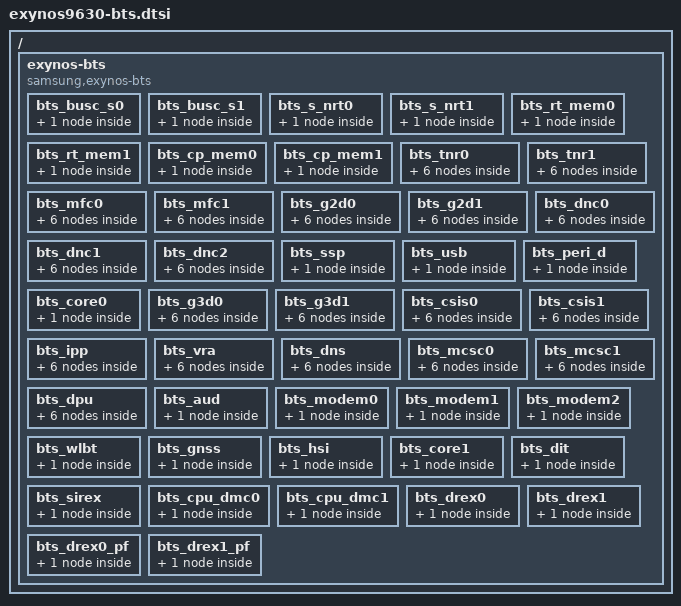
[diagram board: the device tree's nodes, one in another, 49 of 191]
/*
 * SAMSUNG EXYNOS SoC BTS device tree source
 *
 * Copyright (c) 2018 Samsung Electronics Co., Ltd.
 *		http://www.samsung.com
 *
 * SAMSUNG EXYNOS SoC BTS device nodes are listed in this file.
 * EXYNOS based board files should include this file.
 *
 * This program is free software; you can redistribute it and/or modify
 * it under the terms of the GNU General Public License version 2 as
 * published by the Free Software Foundation.
 *
 */

#include <dt-bindings/soc/samsung/exynos-bts.h>
/ {
	exynos-bts {
		compatible = "samsung,exynos-bts";
		#address-cells = <2>;
		#size-cells = <1>;
		ranges;

		list-scen = "default",
			    "mfc_uhd",
			    "g3d_performance",
			    "camera_default",
			    "camera_performance",
			    "camera_thermal";

		bts_busc_s0 {
			reg = <0x0 0x146D2000 0x100>;
			status = "okay";
			bts-type = <BUSC_BTS>;
			default {
				stat_on = <0>;
			};
		};
		bts_busc_s1 {
			reg = <0x0 0x146E2000 0x100>;
			status = "okay";
			bts-type = <BUSC_BTS>;
			default {
				stat_on = <0>;
			};
		};
		bts_s_nrt0 {
			reg = <0x0 0x12172000 0x100>;
			status = "okay";
			bts-type = <BUSC_BTS>;
			default {
				stat_on = <0>;
			};
		};
		bts_s_nrt1 {
			reg = <0x0 0x12182000 0x100>;
			status = "okay";
			bts-type = <BUSC_BTS>;
			default {
				stat_on = <0>;
			};
		};
		bts_rt_mem0 {
			reg = <0x0 0x12192000 0x100>;
			status = "okay";
			bts-type = <BUSC_BTS>;
			default {
				stat_on = <0>;
			};
		};
		bts_rt_mem1 {
			reg = <0x0 0x121A2000 0x100>;
			status = "okay";
			bts-type = <BUSC_BTS>;
			default {
				stat_on = <0>;
			};
		};
		bts_cp_mem0 {
			reg = <0x0 0x121B2000 0x100>;
			status = "okay";
			bts-type = <BUSC_BTS>;
			default {
				stat_on = <0>;
			};
		};
		bts_cp_mem1 {
			reg = <0x0 0x121C2000 0x100>;
			status = "okay";
			bts-type = <BUSC_BTS>;
			default {
				stat_on = <0>;
			};
		};

		bts_tnr0 {
			reg = <0x0 0x14600000 0x100>;
			status = "okay";
			bts-type = <IP_BTS>;
			default {
				stat_on = <1>;
				bypass = <0>;
				arqos = <0x4>;
				awqos = <0x4>;
				rmo = <0x8>;
				wmo = <0x8>;
				qurgent_on = <0>;
				blocking_on = <1>;
				qmax0_limit_r = <0x4>;
				qmax0_limit_w = <0x4>;
			};
			mfc_uhd {
				stat_on = <1>;
				bypass = <0>;
				arqos = <0x4>;
				awqos = <0x4>;
				rmo = <0x8>;
				wmo = <0x8>;
				qurgent_on = <0>;
				blocking_on = <1>;
				qmax0_limit_r = <0x4>;
				qmax0_limit_w = <0x4>;
			};
			g3d_performance {
				stat_on = <1>;
				bypass = <0>;
				arqos = <0x4>;
				awqos = <0x4>;
				rmo = <0x8>;
				wmo = <0x8>;
				qurgent_on = <0>;
				blocking_on = <1>;
				qmax0_limit_r = <0x4>;
				qmax0_limit_w = <0x4>;
			};
			camera_default {
				stat_on = <1>;
				bypass = <0>;
				arqos = <0x4>;
				awqos = <0x4>;
				rmo = <0x8>;
				wmo = <0x8>;
				qurgent_on = <0>;
				blocking_on = <1>;
				qmax0_limit_r = <0x4>;
				qmax0_limit_w = <0x4>;
			};
			camera_performance {
				stat_on = <1>;
				bypass = <0>;
				arqos = <0x4>;
				awqos = <0x4>;
				rmo = <0x8>;
				wmo = <0x8>;
				qurgent_on = <0>;
				blocking_on = <1>;
				qmax0_limit_r = <0x4>;
				qmax0_limit_w = <0x4>;
			};
			camera_thermal {
				stat_on = <1>;
				bypass = <0>;
				arqos = <0x4>;
				awqos = <0x4>;
				rmo = <0x8>;
				wmo = <0x8>;
				qurgent_on = <0>;
				blocking_on = <1>;
				qmax0_limit_r = <0x4>;
				qmax0_limit_w = <0x4>;
			};
		};
		bts_tnr1 {
			reg = <0x0 0x14610000 0x100>;
			status = "okay";
			bts-type = <IP_BTS>;
			default {
				stat_on = <1>;
				bypass = <0>;
				arqos = <0x4>;
				awqos = <0x4>;
				rmo = <0x8>;
				wmo = <0x8>;
				qurgent_on = <0>;
				blocking_on = <1>;
				qmax0_limit_r = <0x4>;
				qmax0_limit_w = <0x4>;
			};
			mfc_uhd {
				stat_on = <1>;
				bypass = <0>;
				arqos = <0x4>;
				awqos = <0x4>;
				rmo = <0x8>;
				wmo = <0x8>;
				qurgent_on = <0>;
				blocking_on = <1>;
				qmax0_limit_r = <0x4>;
				qmax0_limit_w = <0x4>;
			};
			g3d_performance {
				stat_on = <1>;
				bypass = <0>;
				arqos = <0x4>;
				awqos = <0x4>;
				rmo = <0x8>;
				wmo = <0x8>;
				qurgent_on = <0>;
				blocking_on = <1>;
				qmax0_limit_r = <0x4>;
				qmax0_limit_w = <0x4>;
			};
			camera_default {
				stat_on = <1>;
				bypass = <0>;
				arqos = <0x4>;
				awqos = <0x4>;
				rmo = <0x8>;
				wmo = <0x8>;
				qurgent_on = <0>;
				blocking_on = <1>;
				qmax0_limit_r = <0x4>;
				qmax0_limit_w = <0x4>;
			};
			camera_performance {
				stat_on = <1>;
				bypass = <0>;
				arqos = <0x4>;
				awqos = <0x4>;
				rmo = <0x8>;
				wmo = <0x8>;
				qurgent_on = <0>;
				blocking_on = <1>;
				qmax0_limit_r = <0x4>;
				qmax0_limit_w = <0x4>;
			};
			camera_thermal {
				stat_on = <1>;
				bypass = <0>;
				arqos = <0x4>;
				awqos = <0x4>;
				rmo = <0x8>;
				wmo = <0x8>;
				qurgent_on = <0>;
				blocking_on = <1>;
				qmax0_limit_r = <0x4>;
				qmax0_limit_w = <0x4>;
			};
		};
		bts_mfc0 {
			reg = <0x0 0x14620000 0x100>;
			status = "okay";
			bts-type = <IP_BTS>;
			default {
				stat_on = <1>;
				bypass = <0>;
				arqos = <0x4>;
				awqos = <0x4>;
				rmo = <0x8>;
				wmo = <0x8>;
				qurgent_on = <0>;
				blocking_on = <1>;
				qmax0_limit_r = <0x3>;
				qmax0_limit_w = <0x3>;
			};
			mfc_uhd {
				stat_on = <1>;
				bypass = <0>;
				arqos = <0x4>;
				awqos = <0x4>;
				rmo = <0x10>;
				wmo = <0x10>;
				qurgent_on = <0>;
				blocking_on = <1>;
				qmax0_limit_r = <0x3>;
				qmax0_limit_w = <0x3>;
			};
			g3d_performance {
				stat_on = <1>;
				bypass = <0>;
				arqos = <0x4>;
				awqos = <0x4>;
				rmo = <0x8>;
				wmo = <0x8>;
				qurgent_on = <0>;
				blocking_on = <1>;
				qmax0_limit_r = <0x3>;
				qmax0_limit_w = <0x3>;
			};
			camera_default {
				stat_on = <1>;
				bypass = <0>;
				arqos = <0x4>;
				awqos = <0x4>;
				rmo = <0x8>;
				wmo = <0x8>;
				qurgent_on = <0>;
				blocking_on = <1>;
				qmax0_limit_r = <0x3>;
				qmax0_limit_w = <0x3>;
			};
			camera_performance {
				stat_on = <1>;
				bypass = <0>;
				arqos = <0x4>;
				awqos = <0x4>;
				rmo = <0x8>;
				wmo = <0x8>;
				qurgent_on = <0>;
				blocking_on = <1>;
				qmax0_limit_r = <0x3>;
				qmax0_limit_w = <0x3>;
			};
			camera_thermal {
				stat_on = <1>;
				bypass = <0>;
				arqos = <0x4>;
				awqos = <0x4>;
				rmo = <0x8>;
				wmo = <0x8>;
				qurgent_on = <0>;
				blocking_on = <1>;
				qmax0_limit_r = <0x3>;
				qmax0_limit_w = <0x3>;
			};
		};
		bts_mfc1 {
			reg = <0x0 0x14630000 0x100>;
			status = "okay";
			bts-type = <IP_BTS>;
			default {
				stat_on = <1>;
				bypass = <0>;
				arqos = <0x4>;
				awqos = <0x4>;
				rmo = <0x8>;
				wmo = <0x8>;
				qurgent_on = <0>;
				blocking_on = <1>;
				qmax0_limit_r = <0x3>;
				qmax0_limit_w = <0x3>;
			};
			mfc_uhd {
				stat_on = <1>;
				bypass = <0>;
				arqos = <0x4>;
				awqos = <0x4>;
				rmo = <0x10>;
				wmo = <0x10>;
				qurgent_on = <0>;
				blocking_on = <1>;
				qmax0_limit_r = <0x3>;
				qmax0_limit_w = <0x3>;
			};
			g3d_performance {
				stat_on = <1>;
				bypass = <0>;
				arqos = <0x4>;
				awqos = <0x4>;
				rmo = <0x8>;
				wmo = <0x8>;
				qurgent_on = <0>;
				blocking_on = <1>;
				qmax0_limit_r = <0x3>;
				qmax0_limit_w = <0x3>;
			};
			camera_default {
				stat_on = <1>;
				bypass = <0>;
				arqos = <0x4>;
				awqos = <0x4>;
				rmo = <0x8>;
				wmo = <0x8>;
				qurgent_on = <0>;
				blocking_on = <1>;
				qmax0_limit_r = <0x3>;
				qmax0_limit_w = <0x3>;
			};
			camera_performance {
				stat_on = <1>;
				bypass = <0>;
				arqos = <0x4>;
				awqos = <0x4>;
				rmo = <0x8>;
				wmo = <0x8>;
				qurgent_on = <0>;
				blocking_on = <1>;
				qmax0_limit_r = <0x3>;
				qmax0_limit_w = <0x3>;
			};
			camera_thermal {
				stat_on = <1>;
				bypass = <0>;
				arqos = <0x4>;
				awqos = <0x4>;
				rmo = <0x8>;
				wmo = <0x8>;
				qurgent_on = <0>;
				blocking_on = <1>;
				qmax0_limit_r = <0x3>;
				qmax0_limit_w = <0x3>;
			};
		};
		bts_g2d0 {
			reg = <0x0 0x14640000 0x100>;
			status = "okay";
			bts-type = <IP_BTS>;
			default {
				stat_on = <1>;
				bypass = <0>;
				arqos = <0x4>;
				awqos = <0x4>;
				rmo = <0x10>;
				wmo = <0x10>;
				qurgent_on = <0>;
				blocking_on = <1>;
				qmax0_limit_r = <0x1>;
				qmax0_limit_w = <0x1>;
			};
			mfc_uhd {
				stat_on = <1>;
				bypass = <0>;
				arqos = <0x4>;
				awqos = <0x4>;
				rmo = <0x10>;
				wmo = <0x10>;
				qurgent_on = <0>;
				blocking_on = <1>;
				qmax0_limit_r = <0x1>;
				qmax0_limit_w = <0x1>;
			};
			g3d_performance {
				stat_on = <1>;
				bypass = <0>;
				arqos = <0x4>;
				awqos = <0x4>;
				rmo = <0x10>;
				wmo = <0x10>;
				qurgent_on = <0>;
				blocking_on = <1>;
				qmax0_limit_r = <0x1>;
				qmax0_limit_w = <0x1>;
			};
			camera_default {
				stat_on = <1>;
				bypass = <0>;
				arqos = <0x4>;
				awqos = <0x4>;
				rmo = <0x8>;
				wmo = <0x8>;
				qurgent_on = <0>;
				blocking_on = <1>;
				qmax0_limit_r = <0x1>;
				qmax0_limit_w = <0x1>;
			};
			camera_performance {
				stat_on = <1>;
				bypass = <0>;
				arqos = <0x4>;
				awqos = <0x4>;
				rmo = <0x8>;
				wmo = <0x8>;
				qurgent_on = <0>;
				blocking_on = <1>;
				qmax0_limit_r = <0x1>;
				qmax0_limit_w = <0x1>;
			};
			camera_thermal {
				stat_on = <1>;
				bypass = <0>;
				arqos = <0x4>;
				awqos = <0x4>;
				rmo = <0x8>;
				wmo = <0x8>;
				qurgent_on = <0>;
				blocking_on = <1>;
				qmax0_limit_r = <0x1>;
				qmax0_limit_w = <0x1>;
			};
		};
		bts_g2d1 {
			reg = <0x0 0x14650000 0x100>;
			status = "okay";
			bts-type = <IP_BTS>;
			default {
				stat_on = <1>;
				bypass = <0>;
				arqos = <0x4>;
				awqos = <0x4>;
				rmo = <0x8>;
				wmo = <0x8>;
				qurgent_on = <0>;
				blocking_on = <1>;
				qmax0_limit_r = <0x1>;
				qmax0_limit_w = <0x1>;
			};
			mfc_uhd {
				stat_on = <1>;
				bypass = <0>;
				arqos = <0x4>;
				awqos = <0x4>;
				rmo = <0x8>;
				wmo = <0x8>;
				qurgent_on = <0>;
				blocking_on = <1>;
				qmax0_limit_r = <0x1>;
				qmax0_limit_w = <0x1>;
			};
			g3d_performance {
				stat_on = <1>;
				bypass = <0>;
				arqos = <0x4>;
				awqos = <0x4>;
				rmo = <0x8>;
				wmo = <0x8>;
				qurgent_on = <0>;
				blocking_on = <1>;
				qmax0_limit_r = <0x1>;
				qmax0_limit_w = <0x1>;
			};
			camera_default {
				stat_on = <1>;
				bypass = <0>;
				arqos = <0x4>;
				awqos = <0x4>;
				rmo = <0x6>;
				wmo = <0x6>;
				qurgent_on = <0>;
				blocking_on = <1>;
				qmax0_limit_r = <0x1>;
				qmax0_limit_w = <0x1>;
			};
			camera_performance {
				stat_on = <1>;
				bypass = <0>;
				arqos = <0x4>;
				awqos = <0x4>;
				rmo = <0x6>;
				wmo = <0x6>;
				qurgent_on = <0>;
				blocking_on = <1>;
				qmax0_limit_r = <0x1>;
				qmax0_limit_w = <0x1>;
			};
			camera_thermal {
				stat_on = <1>;
				bypass = <0>;
				arqos = <0x4>;
				awqos = <0x4>;
				rmo = <0x6>;
				wmo = <0x6>;
				qurgent_on = <0>;
				blocking_on = <1>;
				qmax0_limit_r = <0x1>;
				qmax0_limit_w = <0x1>;
			};
		};
		bts_dnc0 {
			reg = <0x0 0x14660000 0x100>;
			status = "okay";
			bts-type = <IP_BTS>;
			default {
				stat_on = <1>;
				bypass = <0>;
				arqos = <0x4>;
				awqos = <0x4>;
				rmo = <0x8>;
				wmo = <0x8>;
				qurgent_on = <0>;
				blocking_on = <1>;
				qmax0_limit_r = <0x4>;
				qmax0_limit_w = <0x4>;
			};
			mfc_uhd {
				stat_on = <1>;
				bypass = <0>;
				arqos = <0x4>;
				awqos = <0x4>;
				rmo = <0x8>;
				wmo = <0x8>;
				qurgent_on = <0>;
				blocking_on = <1>;
				qmax0_limit_r = <0x4>;
				qmax0_limit_w = <0x4>;
			};
			g3d_performance {
				stat_on = <1>;
				bypass = <0>;
				arqos = <0x4>;
				awqos = <0x4>;
				rmo = <0x8>;
				wmo = <0x8>;
				qurgent_on = <0>;
				blocking_on = <1>;
				qmax0_limit_r = <0x4>;
				qmax0_limit_w = <0x4>;
			};
			camera_default {
				stat_on = <1>;
				bypass = <0>;
				arqos = <0x4>;
				awqos = <0x4>;
				rmo = <0x8>;
				wmo = <0x8>;
				qurgent_on = <0>;
				blocking_on = <1>;
				qmax0_limit_r = <0x4>;
				qmax0_limit_w = <0x4>;
			};
			camera_performance {
				stat_on = <1>;
				bypass = <0>;
				arqos = <0x4>;
				awqos = <0x4>;
				rmo = <0x8>;
				wmo = <0x8>;
				qurgent_on = <0>;
				blocking_on = <1>;
				qmax0_limit_r = <0x4>;
				qmax0_limit_w = <0x4>;
			};
			camera_thermal {
				stat_on = <1>;
				bypass = <0>;
				arqos = <0x4>;
				awqos = <0x4>;
				rmo = <0x5>;
				wmo = <0x5>;
				qurgent_on = <0>;
				blocking_on = <1>;
				qmax0_limit_r = <0x4>;
				qmax0_limit_w = <0x4>;
			};
		};
		bts_dnc1 {
			reg = <0x0 0x14670000 0x100>;
			status = "okay";
			bts-type = <IP_BTS>;
			default {
				stat_on = <1>;
				bypass = <0>;
				arqos = <0x4>;
				awqos = <0x4>;
				rmo = <0x8>;
				wmo = <0x8>;
				qurgent_on = <0>;
				blocking_on = <1>;
				qmax0_limit_r = <0x4>;
				qmax0_limit_w = <0x4>;
			};
			mfc_uhd {
				stat_on = <1>;
				bypass = <0>;
				arqos = <0x4>;
				awqos = <0x4>;
				rmo = <0x8>;
				wmo = <0x8>;
				qurgent_on = <0>;
				blocking_on = <1>;
				qmax0_limit_r = <0x4>;
				qmax0_limit_w = <0x4>;
			};
			g3d_performance {
				stat_on = <1>;
				bypass = <0>;
				arqos = <0x4>;
				awqos = <0x4>;
				rmo = <0x8>;
				wmo = <0x8>;
				qurgent_on = <0>;
				blocking_on = <1>;
				qmax0_limit_r = <0x4>;
				qmax0_limit_w = <0x4>;
			};
			camera_default {
				stat_on = <1>;
				bypass = <0>;
				arqos = <0x4>;
				awqos = <0x4>;
				rmo = <0x8>;
				wmo = <0x8>;
				qurgent_on = <0>;
				blocking_on = <1>;
				qmax0_limit_r = <0x4>;
				qmax0_limit_w = <0x4>;
			};
			camera_performance {
				stat_on = <1>;
				bypass = <0>;
				arqos = <0x4>;
				awqos = <0x4>;
				rmo = <0x8>;
				wmo = <0x8>;
				qurgent_on = <0>;
				blocking_on = <1>;
				qmax0_limit_r = <0x4>;
				qmax0_limit_w = <0x4>;
			};
			camera_thermal {
				stat_on = <1>;
				bypass = <0>;
				arqos = <0x4>;
				awqos = <0x4>;
				rmo = <0x5>;
				wmo = <0x5>;
				qurgent_on = <0>;
				blocking_on = <1>;
				qmax0_limit_r = <0x4>;
				qmax0_limit_w = <0x4>;
			};
		};
		bts_dnc2 {
			reg = <0x0 0x14680000 0x100>;
			status = "okay";
			bts-type = <IP_BTS>;
			default {
				stat_on = <1>;
				bypass = <0>;
				arqos = <0x4>;
				awqos = <0x4>;
				rmo = <0x8>;
				wmo = <0x8>;
				qurgent_on = <0>;
				blocking_on = <1>;
				qmax0_limit_r = <0x4>;
				qmax0_limit_w = <0x4>;
			};
			mfc_uhd {
				stat_on = <1>;
				bypass = <0>;
				arqos = <0x4>;
				awqos = <0x4>;
				rmo = <0x8>;
				wmo = <0x8>;
				qurgent_on = <0>;
				blocking_on = <1>;
				qmax0_limit_r = <0x4>;
				qmax0_limit_w = <0x4>;
			};
			g3d_performance {
				stat_on = <1>;
				bypass = <0>;
				arqos = <0x4>;
				awqos = <0x4>;
				rmo = <0x8>;
				wmo = <0x8>;
				qurgent_on = <0>;
				blocking_on = <1>;
				qmax0_limit_r = <0x4>;
				qmax0_limit_w = <0x4>;
			};
			camera_default {
				stat_on = <1>;
				bypass = <0>;
				arqos = <0x4>;
				awqos = <0x4>;
				rmo = <0x8>;
				wmo = <0x8>;
				qurgent_on = <0>;
				blocking_on = <1>;
				qmax0_limit_r = <0x4>;
				qmax0_limit_w = <0x4>;
			};
			camera_performance {
				stat_on = <1>;
				bypass = <0>;
				arqos = <0x4>;
				awqos = <0x4>;
				rmo = <0x8>;
				wmo = <0x8>;
				qurgent_on = <0>;
				blocking_on = <1>;
				qmax0_limit_r = <0x4>;
				qmax0_limit_w = <0x4>;
			};
			camera_thermal {
				stat_on = <1>;
				bypass = <0>;
				arqos = <0x4>;
				awqos = <0x4>;
				rmo = <0x5>;
				wmo = <0x5>;
				qurgent_on = <0>;
				blocking_on = <1>;
				qmax0_limit_r = <0x4>;
				qmax0_limit_w = <0x4>;
			};
		};
		bts_ssp {
			reg = <0x0 0x14690000 0x100>;
			status = "okay";
			bts-type = <IP_BTS>;
			default {
				stat_on = <1>;
				bypass = <0>;
				arqos = <0x4>;
				awqos = <0x4>;
				rmo = <0x4>;
				wmo = <0x4>;
				qurgent_on = <0>;
				blocking_on = <1>;
				qmax0_limit_r = <0x1>;
				qmax0_limit_w = <0x1>;
			};
		};
		bts_usb {
			reg = <0x0 0x146A0000 0x100>;
			status = "okay";
			bts-type = <IP_BTS>;
			default {
				stat_on = <1>;
				bypass = <0>;
				arqos = <0x4>;
				awqos = <0x4>;
				rmo = <0x4>;
				wmo = <0x4>;
				qurgent_on = <0>;
				blocking_on = <1>;
				qmax0_limit_r = <0x1>;
				qmax0_limit_w = <0x1>;
			};
		};
		bts_peri_d {
			reg = <0x0 0x146B0000 0x100>;
			status = "okay";
			bts-type = <IP_BTS>;
			default {
				stat_on = <1>;
				bypass = <0>;
				arqos = <0x4>;
				awqos = <0x4>;
				rmo = <0x4>;
				wmo = <0x4>;
				qurgent_on = <0>;
				blocking_on = <1>;
				qmax0_limit_r = <0x1>;
				qmax0_limit_w = <0x1>;
			};
		};
		bts_core0 {
			reg = <0x0 0x146C0000 0x100>;
			status = "okay";
			bts-type = <IP_BTS>;
			default {
				stat_on = <1>;
				bypass = <0>;
				arqos = <0x4>;
				awqos = <0x4>;
				rmo = <0x4>;
				wmo = <0x4>;
				qurgent_on = <0>;
				blocking_on = <0>;
			};
		};
		bts_g3d0 {
			reg = <0x0 0x12030000 0x100>;
			status = "okay";
			bts-type = <IP_BTS>;
			default {
				stat_on = <1>;
				bypass = <0>;
				arqos = <0x4>;
				awqos = <0x4>;
				rmo = <0x4>;
				wmo = <0x4>;
				qurgent_on = <0>;
				blocking_on = <1>;
				qmax0_limit_r = <0x1>;
				qmax0_limit_w = <0x1>;
			};
			mfc_uhd {
				stat_on = <1>;
				bypass = <0>;
				arqos = <0x4>;
				awqos = <0x4>;
				rmo = <0x4>;
				wmo = <0x4>;
				qurgent_on = <0>;
				blocking_on = <1>;
				qmax0_limit_r = <0x1>;
				qmax0_limit_w = <0x1>;
			};
			g3d_performance {
				stat_on = <1>;
				bypass = <0>;
				arqos = <0x4>;
				awqos = <0x4>;
				qurgent_on = <0>;
				blocking_on = <0>;
			};
			camera_default {
				stat_on = <1>;
				bypass = <0>;
				arqos = <0x4>;
				awqos = <0x4>;
				rmo = <0x2>;
				wmo = <0x2>;
				qurgent_on = <0>;
				blocking_on = <1>;
				qmax0_limit_r = <0x1>;
				qmax0_limit_w = <0x1>;
			};
			camera_performance {
				stat_on = <1>;
				bypass = <0>;
				arqos = <0x4>;
				awqos = <0x4>;
				rmo = <0x2>;
				wmo = <0x2>;
				qurgent_on = <0>;
				blocking_on = <1>;
				qmax0_limit_r = <0x1>;
				qmax0_limit_w = <0x1>;
			};
			camera_thermal {
				stat_on = <1>;
				bypass = <0>;
				arqos = <0x4>;
				awqos = <0x4>;
				rmo = <0x2>;
				wmo = <0x2>;
				qurgent_on = <0>;
				blocking_on = <1>;
				qmax0_limit_r = <0x1>;
				qmax0_limit_w = <0x1>;
			};
		};
		bts_g3d1 {
			reg = <0x0 0x12040000 0x100>;
			status = "okay";
			bts-type = <IP_BTS>;
			default {
				stat_on = <1>;
				bypass = <0>;
				arqos = <0x4>;
				awqos = <0x4>;
				rmo = <0x4>;
				wmo = <0x4>;
				qurgent_on = <0>;
				blocking_on = <1>;
				qmax0_limit_r = <0x1>;
				qmax0_limit_w = <0x1>;
			};
			mfc_uhd {
				stat_on = <1>;
				bypass = <0>;
				arqos = <0x4>;
				awqos = <0x4>;
				rmo = <0x4>;
				wmo = <0x4>;
				qurgent_on = <0>;
				blocking_on = <1>;
				qmax0_limit_r = <0x1>;
				qmax0_limit_w = <0x1>;
			};
			g3d_performance {
				stat_on = <1>;
				bypass = <0>;
				arqos = <0x4>;
				awqos = <0x4>;
				qurgent_on = <0>;
				blocking_on = <0>;
			};
			camera_default {
				stat_on = <1>;
				bypass = <0>;
				arqos = <0x4>;
				awqos = <0x4>;
				rmo = <0x2>;
				wmo = <0x2>;
				qurgent_on = <0>;
				blocking_on = <1>;
				qmax0_limit_r = <0x1>;
				qmax0_limit_w = <0x1>;
			};
			camera_performance {
				stat_on = <1>;
				bypass = <0>;
				arqos = <0x4>;
				awqos = <0x4>;
				rmo = <0x2>;
				wmo = <0x2>;
				qurgent_on = <0>;
				blocking_on = <1>;
				qmax0_limit_r = <0x1>;
				qmax0_limit_w = <0x1>;
			};
			camera_thermal {
				stat_on = <1>;
				bypass = <0>;
				arqos = <0x4>;
				awqos = <0x4>;
				rmo = <0x2>;
				wmo = <0x2>;
				qurgent_on = <0>;
				blocking_on = <1>;
				qmax0_limit_r = <0x1>;
				qmax0_limit_w = <0x1>;
			};
		};
		bts_csis0 {
			reg = <0x0 0x12050000 0x100>;
			status = "okay";
			bts-type = <IP_BTS>;
			default {
				stat_on = <1>;
				bypass = <0>;
				arqos = <0xC>;
				awqos = <0xC>;
				rmo = <0xA>;
				wmo = <0xA>;
				qurgent_on = <1>;
				qurgent_th_r = <0xF>;
				qurgent_th_w = <0xF>;
				blocking_on = <0>;
			};
			mfc_uhd {
				stat_on = <1>;
				bypass = <0>;
				arqos = <0xC>;
				awqos = <0xC>;
				rmo = <0xA>;
				wmo = <0xA>;
				qurgent_on = <1>;
				qurgent_th_r = <0xF>;
				qurgent_th_w = <0xF>;
				blocking_on = <0>;
			};
			g3d_performance {
				stat_on = <1>;
				bypass = <0>;
				arqos = <0xC>;
				awqos = <0xC>;
				rmo = <0xA>;
				wmo = <0xA>;
				qurgent_on = <1>;
				qurgent_th_r = <0xF>;
				qurgent_th_w = <0xF>;
				blocking_on = <0>;
			};
			camera_default {
				stat_on = <1>;
				bypass = <0>;
				arqos = <0xC>;
				awqos = <0xC>;
				rmo = <0xA>;
				wmo = <0xA>;
				qurgent_on = <1>;
				qurgent_th_r = <0xF>;
				qurgent_th_w = <0xF>;
				blocking_on = <0>;
			};
			camera_performance {
				stat_on = <1>;
				bypass = <0>;
				arqos = <0xC>;
				awqos = <0xC>;
				rmo = <0xA>;
				wmo = <0xA>;
				qurgent_on = <1>;
				qurgent_th_r = <0xF>;
				qurgent_th_w = <0xF>;
				blocking_on = <0>;
			};
			camera_thermal {
				stat_on = <1>;
				bypass = <0>;
				arqos = <0xC>;
				awqos = <0xC>;
				rmo = <0xA>;
				wmo = <0xA>;
				qurgent_on = <1>;
				qurgent_th_r = <0xF>;
				qurgent_th_w = <0xF>;
				blocking_on = <0>;
			};
		};
		bts_csis1 {
			reg = <0x0 0x12060000 0x100>;
			status = "okay";
			bts-type = <IP_BTS>;
			default {
				stat_on = <1>;
				bypass = <0>;
				arqos = <0xC>;
				awqos = <0xC>;
				rmo = <0xA>;
				wmo = <0xA>;
				qurgent_on = <1>;
				qurgent_th_r = <0xF>;
				qurgent_th_w = <0xF>;
				blocking_on = <0>;
			};
			mfc_uhd {
				stat_on = <1>;
				bypass = <0>;
				arqos = <0xC>;
				awqos = <0xC>;
				rmo = <0xA>;
				wmo = <0xA>;
				qurgent_on = <1>;
				qurgent_th_r = <0xF>;
				qurgent_th_w = <0xF>;
				blocking_on = <0>;
			};
			g3d_performance {
				stat_on = <1>;
				bypass = <0>;
				arqos = <0xC>;
				awqos = <0xC>;
				rmo = <0xA>;
				wmo = <0xA>;
				qurgent_on = <1>;
				qurgent_th_r = <0xF>;
				qurgent_th_w = <0xF>;
				blocking_on = <0>;
			};
			camera_default {
				stat_on = <1>;
				bypass = <0>;
				arqos = <0xC>;
				awqos = <0xC>;
				rmo = <0xA>;
				wmo = <0xA>;
				qurgent_on = <1>;
				qurgent_th_r = <0xF>;
				qurgent_th_w = <0xF>;
				blocking_on = <0>;
			};
			camera_performance {
				stat_on = <1>;
				bypass = <0>;
				arqos = <0xC>;
				awqos = <0xC>;
				rmo = <0xA>;
				wmo = <0xA>;
				qurgent_on = <1>;
				qurgent_th_r = <0xF>;
				qurgent_th_w = <0xF>;
				blocking_on = <0>;
			};
			camera_thermal {
				stat_on = <1>;
				bypass = <0>;
				arqos = <0xC>;
				awqos = <0xC>;
				rmo = <0xA>;
				wmo = <0xA>;
				qurgent_on = <1>;
				qurgent_th_r = <0xF>;
				qurgent_th_w = <0xF>;
				blocking_on = <0>;
			};
		};
		bts_ipp {
			reg = <0x0 0x12070000 0x100>;
			status = "okay";
			bts-type = <IP_BTS>;
			default {
				stat_on = <1>;
				bypass = <0>;
				arqos = <0xC>;
				awqos = <0xC>;
				rmo = <0x8>;
				wmo = <0x8>;
				qurgent_on = <1>;
				qurgent_th_r = <0xF>;
				qurgent_th_w = <0xF>;
				blocking_on = <0>;
			};
			mfc_uhd {
				stat_on = <1>;
				bypass = <0>;
				arqos = <0xC>;
				awqos = <0xC>;
				rmo = <0x8>;
				wmo = <0x8>;
				qurgent_on = <1>;
				qurgent_th_r = <0xF>;
				qurgent_th_w = <0xF>;
				blocking_on = <0>;
			};
			g3d_performance {
				stat_on = <1>;
				bypass = <0>;
				arqos = <0xC>;
				awqos = <0xC>;
				rmo = <0x8>;
				wmo = <0x8>;
				qurgent_on = <1>;
				qurgent_th_r = <0xF>;
				qurgent_th_w = <0xF>;
				blocking_on = <0>;
			};
			camera_default {
				stat_on = <1>;
				bypass = <0>;
				arqos = <0xC>;
				awqos = <0xC>;
				rmo = <0x8>;
				wmo = <0x8>;
				qurgent_on = <1>;
				qurgent_th_r = <0xF>;
				qurgent_th_w = <0xF>;
				blocking_on = <0>;
			};
			camera_performance {
				stat_on = <1>;
				bypass = <0>;
				arqos = <0xC>;
				awqos = <0xC>;
				rmo = <0x8>;
				wmo = <0x8>;
				qurgent_on = <1>;
				qurgent_th_r = <0xF>;
				qurgent_th_w = <0xF>;
				blocking_on = <0>;
			};
			camera_thermal {
				stat_on = <1>;
				bypass = <0>;
				arqos = <0xC>;
				awqos = <0xC>;
				rmo = <0x8>;
				wmo = <0x8>;
				qurgent_on = <1>;
				qurgent_th_r = <0xF>;
				qurgent_th_w = <0xF>;
				blocking_on = <0>;
			};
		};
		bts_vra {
			reg = <0x0 0x12080000 0x100>;
			status = "okay";
			bts-type = <IP_BTS>;
			default {
				stat_on = <1>;
				bypass = <0>;
				arqos = <0x4>;
				awqos = <0x4>;
				rmo = <0x4>;
				wmo = <0x4>;
				qurgent_on = <0>;
				blocking_on = <1>;
				qmax0_limit_r = <0x1>;
				qmax0_limit_w = <0x1>;
			};
			mfc_uhd {
				stat_on = <1>;
				bypass = <0>;
				arqos = <0x4>;
				awqos = <0x4>;
				rmo = <0x4>;
				wmo = <0x4>;
				qurgent_on = <0>;
				blocking_on = <1>;
				qmax0_limit_r = <0x1>;
				qmax0_limit_w = <0x1>;
			};
			g3d_performance {
				stat_on = <1>;
				bypass = <0>;
				arqos = <0x4>;
				awqos = <0x4>;
				rmo = <0x4>;
				wmo = <0x4>;
				qurgent_on = <0>;
				blocking_on = <1>;
				qmax0_limit_r = <0x1>;
				qmax0_limit_w = <0x1>;
			};
			camera_default {
				stat_on = <1>;
				bypass = <0>;
				arqos = <0x4>;
				awqos = <0x4>;
				rmo = <0x4>;
				wmo = <0x4>;
				qurgent_on = <0>;
				blocking_on = <1>;
				qmax0_limit_r = <0x1>;
				qmax0_limit_w = <0x1>;
			};
			camera_performance {
				stat_on = <1>;
				bypass = <0>;
				arqos = <0x4>;
				awqos = <0x4>;
				rmo = <0x4>;
				wmo = <0x4>;
				qurgent_on = <0>;
				blocking_on = <1>;
				qmax0_limit_r = <0x1>;
				qmax0_limit_w = <0x1>;
			};
			camera_thermal {
				stat_on = <1>;
				bypass = <0>;
				arqos = <0x4>;
				awqos = <0x4>;
				rmo = <0x3>;
				wmo = <0x3>;
				qurgent_on = <0>;
				blocking_on = <1>;
				qmax0_limit_r = <0x1>;
				qmax0_limit_w = <0x1>;
			};
		};
		bts_dns {
			reg = <0x0 0x12090000 0x100>;
			status = "okay";
			bts-type = <IP_BTS>;
			default {
				stat_on = <1>;
				bypass = <0>;
				arqos = <0x4>;
				awqos = <0x4>;
				rmo = <0x8>;
				wmo = <0x1>;
				qurgent_on = <0>;
				blocking_on = <1>;
				qmax0_limit_r = <0x4>;
				qmax0_limit_w = <0x1>;
			};
			mfc_uhd {
				stat_on = <1>;
				bypass = <0>;
				arqos = <0x4>;
				awqos = <0x4>;
				rmo = <0x8>;
				wmo = <0x1>;
				qurgent_on = <0>;
				blocking_on = <1>;
				qmax0_limit_r = <0x4>;
				qmax0_limit_w = <0x1>;
			};
			g3d_performance {
				stat_on = <1>;
				bypass = <0>;
				arqos = <0x4>;
				awqos = <0x4>;
				rmo = <0x8>;
				wmo = <0x1>;
				qurgent_on = <0>;
				blocking_on = <1>;
				qmax0_limit_r = <0x4>;
				qmax0_limit_w = <0x1>;
			};
			camera_default {
				stat_on = <1>;
				bypass = <0>;
				arqos = <0x4>;
				awqos = <0x4>;
				rmo = <0x8>;
				wmo = <0x1>;
				qurgent_on = <0>;
				blocking_on = <1>;
				qmax0_limit_r = <0x4>;
				qmax0_limit_w = <0x1>;
			};
			camera_performance {
				stat_on = <1>;
				bypass = <0>;
				arqos = <0x4>;
				awqos = <0x4>;
				rmo = <0x8>;
				wmo = <0x1>;
				qurgent_on = <0>;
				blocking_on = <1>;
				qmax0_limit_r = <0x4>;
				qmax0_limit_w = <0x1>;
			};
			camera_thermal {
				stat_on = <1>;
				bypass = <0>;
				arqos = <0x4>;
				awqos = <0x4>;
				rmo = <0x8>;
				wmo = <0x1>;
				qurgent_on = <0>;
				blocking_on = <1>;
				qmax0_limit_r = <0x4>;
				qmax0_limit_w = <0x1>;
			};
		};
		bts_mcsc0 {
			reg = <0x0 0x120A0000 0x100>;
			status = "okay";
			bts-type = <IP_BTS>;
			default {
				stat_on = <1>;
				bypass = <0>;
				arqos = <0x4>;
				awqos = <0x4>;
				rmo = <0xA>;
				wmo = <0x8>;
				qurgent_on = <0>;
				blocking_on = <1>;
				qmax0_limit_r = <0x4>;
				qmax0_limit_w = <0x4>;
			};
			mfc_uhd {
				stat_on = <1>;
				bypass = <0>;
				arqos = <0x4>;
				awqos = <0x4>;
				rmo = <0xA>;
				wmo = <0x8>;
				qurgent_on = <0>;
				blocking_on = <1>;
				qmax0_limit_r = <0x4>;
				qmax0_limit_w = <0x4>;
			};
			g3d_performance {
				stat_on = <1>;
				bypass = <0>;
				arqos = <0x4>;
				awqos = <0x4>;
				rmo = <0xA>;
				wmo = <0x8>;
				qurgent_on = <0>;
				blocking_on = <1>;
				qmax0_limit_r = <0x4>;
				qmax0_limit_w = <0x4>;
			};
			camera_default {
				stat_on = <1>;
				bypass = <0>;
				arqos = <0x4>;
				awqos = <0x4>;
				rmo = <0xA>;
				wmo = <0x8>;
				qurgent_on = <0>;
				blocking_on = <1>;
				qmax0_limit_r = <0x4>;
				qmax0_limit_w = <0x4>;
			};
			camera_performance {
				stat_on = <1>;
				bypass = <0>;
				arqos = <0x4>;
				awqos = <0x4>;
				rmo = <0xA>;
				wmo = <0x8>;
				qurgent_on = <0>;
				blocking_on = <1>;
				qmax0_limit_r = <0x4>;
				qmax0_limit_w = <0x4>;
			};
			camera_thermal {
				stat_on = <1>;
				bypass = <0>;
				arqos = <0x4>;
				awqos = <0x4>;
				rmo = <0x4>;
				wmo = <0x4>;
				qurgent_on = <0>;
				blocking_on = <1>;
				qmax0_limit_r = <0x4>;
				qmax0_limit_w = <0x4>;
			};
		};
		bts_mcsc1 {
			reg = <0x0 0x120B0000 0x100>;
			status = "okay";
			bts-type = <IP_BTS>;
			default {
				stat_on = <1>;
				bypass = <0>;
				arqos = <0xC>;
				awqos = <0xC>;
				rmo = <0xA>;
				wmo = <0xA>;
				qurgent_on = <1>;
				qurgent_th_r = <0xF>;
				qurgent_th_w = <0xF>;
				blocking_on = <0>;
			};
			mfc_uhd {
				stat_on = <1>;
				bypass = <0>;
				arqos = <0xC>;
				awqos = <0xC>;
				rmo = <0xA>;
				wmo = <0xA>;
				qurgent_on = <1>;
				qurgent_th_r = <0xF>;
				qurgent_th_w = <0xF>;
				blocking_on = <0>;
			};
			g3d_performance {
				stat_on = <1>;
				bypass = <0>;
				arqos = <0xC>;
				awqos = <0xC>;
				rmo = <0xA>;
				wmo = <0xA>;
				qurgent_on = <1>;
				qurgent_th_r = <0xF>;
				qurgent_th_w = <0xF>;
				blocking_on = <0>;
			};
			camera_default {
				stat_on = <1>;
				bypass = <0>;
				arqos = <0xC>;
				awqos = <0xC>;
				rmo = <0xA>;
				wmo = <0xA>;
				qurgent_on = <1>;
				qurgent_th_r = <0xF>;
				qurgent_th_w = <0xF>;
				blocking_on = <0>;
			};
			camera_performance {
				stat_on = <1>;
				bypass = <0>;
				arqos = <0xC>;
				awqos = <0xC>;
				rmo = <0xA>;
				wmo = <0xA>;
				qurgent_on = <1>;
				qurgent_th_r = <0xF>;
				qurgent_th_w = <0xF>;
				blocking_on = <0>;
			};
			camera_thermal {
				stat_on = <1>;
				bypass = <0>;
				arqos = <0xC>;
				awqos = <0xC>;
				rmo = <0xA>;
				wmo = <0xA>;
				qurgent_on = <1>;
				qurgent_th_r = <0xF>;
				qurgent_th_w = <0xF>;
				blocking_on = <0>;
			};
		};
		bts_dpu {
			reg = <0x0 0x120C0000 0x100>;
			status = "okay";
			bts-type = <IP_BTS>;
			default {
				stat_on = <1>;
				bypass = <0>;
				arqos = <0xA>;
				awqos = <0xA>;
				rmo = <0x20>;
				wmo = <0x20>;
				qurgent_on = <1>;
				qurgent_th_r = <0x20>;
				blocking_on = <0>;
			};
			mfc_uhd {
				stat_on = <1>;
				bypass = <0>;
				arqos = <0xA>;
				awqos = <0xA>;
				rmo = <0x20>;
				wmo = <0x20>;
				qurgent_on = <1>;
				qurgent_th_r = <0x20>;
				blocking_on = <0>;
			};
			g3d_performance {
				stat_on = <1>;
				bypass = <0>;
				arqos = <0xA>;
				awqos = <0xA>;
				rmo = <0x20>;
				wmo = <0x20>;
				qurgent_on = <1>;
				qurgent_th_r = <0x20>;
				blocking_on = <0>;
			};
			camera_default {
				stat_on = <1>;
				bypass = <0>;
				arqos = <0xA>;
				awqos = <0xA>;
				rmo = <0x20>;
				wmo = <0x20>;
				qurgent_on = <1>;
				qurgent_th_r = <0x20>;
				blocking_on = <0>;
			};
			camera_performance {
				stat_on = <1>;
				bypass = <0>;
				arqos = <0xA>;
				awqos = <0xA>;
				rmo = <0x20>;
				wmo = <0x20>;
				qurgent_on = <1>;
				qurgent_th_r = <0x20>;
				blocking_on = <0>;
			};
			camera_thermal {
				stat_on = <1>;
				bypass = <0>;
				arqos = <0xA>;
				awqos = <0xA>;
				rmo = <0x20>;
				wmo = <0x20>;
				qurgent_on = <1>;
				qurgent_th_r = <0x20>;
				blocking_on = <0>;
			};
		};
		bts_aud {
			reg = <0x0 0x120D0000 0x100>;
			status = "okay";
			bts-type = <IP_BTS>;
			default {
				stat_on = <1>;
				bypass = <0>;
				arqos = <0xC>;
				awqos = <0xC>;
				qurgent_on = <0>;
				blocking_on = <0>;
			};
		};
		bts_modem0 {
			reg = <0x0 0x120E0000 0x100>;
			status = "okay";
			bts-type = <IP_BTS>;
			default {
				stat_on = <1>;
				bypass = <0>;
				arqos = <0xD>;
				awqos = <0xD>;
				qurgent_on = <1>;
				qurgent_th_r = <0xC>;
				qurgent_th_w = <0xA>;
				blocking_on = <0>;
			};
		};
		bts_modem1 {
			reg = <0x0 0x120F0000 0x100>;
			status = "okay";
			bts-type = <IP_BTS>;
			default {
				stat_on = <1>;
				bypass = <0>;
				arqos = <0x4>;
				awqos = <0x4>;
				qurgent_on = <0>;
				blocking_on = <0>;
			};
		};
		bts_modem2 {
			reg = <0x0 0x12100000 0x100>;
			status = "okay";
			bts-type = <IP_BTS>;
			default {
				stat_on = <1>;
				bypass = <0>;
				arqos = <0x4>;
				awqos = <0x4>;
				qurgent_on = <0>;
				blocking_on = <0>;
			};
		};
		bts_wlbt {
			reg = <0x0 0x12110000 0x100>;
			status = "okay";
			bts-type = <IP_BTS>;
			default {
				stat_on = <1>;
				bypass = <0>;
				arqos = <0x4>;
				awqos = <0x4>;
				rmo = <0x4>;
				wmo = <0x4>;
				qurgent_on = <0>;
				blocking_on = <1>;
				qmax0_limit_r = <0x1>;
				qmax0_limit_w = <0x1>;
			};
		};
		bts_gnss {
			reg = <0x0 0x12120000 0x100>;
			status = "okay";
			bts-type = <IP_BTS>;
			default {
				stat_on = <1>;
				bypass = <0>;
				arqos = <0x4>;
				awqos = <0x4>;
				rmo = <0x4>;
				wmo = <0x4>;
				qurgent_on = <0>;
				blocking_on = <1>;
				qmax0_limit_r = <0x1>;
				qmax0_limit_w = <0x1>;
			};
		};
		bts_hsi {
			reg = <0x0 0x12130000 0x100>;
			status = "okay";
			bts-type = <IP_BTS>;
			default {
				stat_on = <1>;
				bypass = <0>;
				arqos = <0x4>;
				awqos = <0x4>;
				rmo = <0x4>;
				wmo = <0x4>;
				qurgent_on = <0>;
				blocking_on = <1>;
				qmax0_limit_r = <0x1>;
				qmax0_limit_w = <0x1>;
			};
		};
		bts_core1 {
			reg = <0x0 0x12140000 0x100>;
			status = "okay";
			bts-type = <IP_BTS>;
			default {
				stat_on = <1>;
				bypass = <0>;
				arqos = <0x4>;
				awqos = <0x4>;
				rmo = <0x4>;
				wmo = <0x4>;
				qurgent_on = <0>;
				blocking_on = <1>;
				qmax0_limit_r = <0x2>;
				qmax0_limit_w = <0x2>;
			};
		};
		bts_dit {
			reg = <0x0 0x12150000 0x100>;
			status = "okay";
			bts-type = <IP_BTS>;
			default {
				stat_on = <1>;
				bypass = <0>;
				arqos = <0x4>;
				awqos = <0x4>;
				rmo = <0x4>;
				wmo = <0x4>;
				qurgent_on = <0>;
				blocking_on = <1>;
				qmax0_limit_r = <0x1>;
				qmax0_limit_w = <0x1>;
			};
		};
		bts_sirex {
			reg = <0x0 0x12800000 0x100>;
			status = "okay";
			bts-type = <IP_BTS>;
			default {
				stat_on = <1>;
				bypass = <0>;
				arqos = <0x4>;
				awqos = <0x4>;
				rmo = <0x4>;
				wmo = <0x4>;
				qurgent_on = <0>;
				blocking_on = <1>;
				qmax0_limit_r = <0x1>;
				qmax0_limit_w = <0x1>;
			};
		};
		bts_cpu_dmc0 {
			reg = <0x0 0x10490000 0x100>;
			status = "okay";
			bts-type = <IP_BTS>;
			default {
				stat_on = <1>;
				bypass = <0>;
				arqos = <0x0>;
				awqos = <0x0>;
				qurgent_on = <0>;
				blocking_on = <0>;
			};
		};
		bts_cpu_dmc1 {
			reg = <0x0 0x10590000 0x100>;
			status = "okay";
			bts-type = <IP_BTS>;
			default {
				stat_on = <1>;
				bypass = <0>;
				arqos = <0x0>;
				awqos = <0x0>;
				qurgent_on = <0>;
				blocking_on = <0>;
			};
		};

		bts_drex0 {
			reg = <0x0 0x10450000 0x1000>;
			status = "okay";
			bts-type = <DREX_BTS>;
			default {
				stat_on = <1>;
				bypass = <0>;
				qurgent_on = <0>;
				blocking_on = <0>;
				drex_on = <1>;
				drex_pf_on = <0>;
				write_flush_config_0 = <0xB4301606>;
				write_flush_config_1 = <0x1810100A>;
				drex_timeout = <0x000A0180>,
						<0x000A0100>,
						<0x000A0100>,
						<0x000A0100>,
						<0x000A0100>,
						<0x000A0100>,
						<0x000A0100>,
						<0x000A0100>,
						<0x000A0080>,
						<0x000A0060>,
						<0x000A0040>,
						<0x000A0020>,
						<0x000A0010>,
						<0x000A0008>,
						<0x000A0004>,
						<0x000A0001>;
				vc_timer_th = <0x00C100C1>,
						<0x00C100C1>,
						<0x00C100C1>,
						<0x00C100C1>,
						<0x00C100C1>,
						<0x000D001A>,
						<0x00030007>,
						<0x00010001>;
				cutoff_con = <0x00000505>;
				brb_cutoff_con = <0x00020002>;
				wdbuf_cutoff_con = <0x00100010>;
			};
		};
		bts_drex1 {
			reg = <0x0 0x10550000 0x1000>;
			status = "okay";
			bts-type = <DREX_BTS>;
			default {
				stat_on = <1>;
				bypass = <0>;
				qurgent_on = <0>;
				blocking_on = <0>;
				drex_on = <1>;
				drex_pf_on = <0>;
				write_flush_config_0 = <0xB4301606>;
				write_flush_config_1 = <0x1810100A>;
				drex_timeout = <0x000A0180>,
						<0x000A0100>,
						<0x000A0100>,
						<0x000A0100>,
						<0x000A0100>,
						<0x000A0100>,
						<0x000A0100>,
						<0x000A0100>,
						<0x000A0080>,
						<0x000A0060>,
						<0x000A0040>,
						<0x000A0020>,
						<0x000A0010>,
						<0x000A0008>,
						<0x000A0004>,
						<0x000A0001>;
				vc_timer_th = <0x00C100C1>,
						<0x00C100C1>,
						<0x00C100C1>,
						<0x00C100C1>,
						<0x00C100C1>,
						<0x000D001A>,
						<0x00030007>,
						<0x00010001>;
				cutoff_con = <0x00000505>;
				brb_cutoff_con = <0x00020002>;
				wdbuf_cutoff_con = <0x00100010>;
			};
		};

		bts_drex0_pf {
			reg = <0x0 0x10460000 0x100>;
			status = "okay";
			bts-type = <DREX_BTS>;
			default {
				stat_on = <1>;
				bypass = <0>;
				qurgent_on = <0>;
				blocking_on = <0>;
				drex_on = <0>;
				drex_pf_on = <1>;
				pf_rreq_thrt_con = <0x00008000>;
				allow_mo_for_region = <0x00000000>;
				pf_qos_timer = <0x00050005>,
						<0x00050005>,
						<0x00050005>,
						<0x00050005>,
						<0x00050005>,
						<0x00050005>,
						<0x00050005>,
						<0x00050005>;
			};
		};
		bts_drex1_pf {
			reg = <0x0 0x10560000 0x100>;
			status = "okay";
			bts-type = <DREX_BTS>;
			default {
				stat_on = <1>;
				bypass = <0>;
				qurgent_on = <0>;
				blocking_on = <0>;
				drex_on = <0>;
				drex_pf_on = <1>;
				pf_rreq_thrt_con = <0x00008000>;
				allow_mo_for_region = <0x00000000>;
				pf_qos_timer = <0x00050005>,
						<0x00050005>,
						<0x00050005>,
						<0x00050005>,
						<0x00050005>,
						<0x00050005>,
						<0x00050005>,
						<0x00050005>;
			};

		};

	};

};
